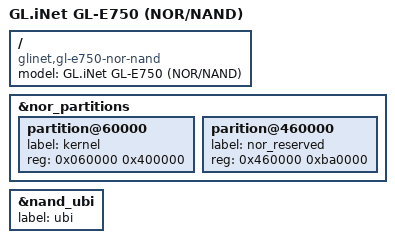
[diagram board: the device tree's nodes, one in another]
// SPDX-License-Identifier: GPL-2.0-or-later OR MIT

/dts-v1/;

#include "qca9531_glinet_gl-e750.dtsi"

/ {
	compatible = "glinet,gl-e750-nor-nand", "qca,qca9531";
	model = "GL.iNet GL-E750 (NOR/NAND)";
};

&nor_partitions {
	partition@60000 {
		label = "kernel";
		reg = <0x060000 0x400000>;
	};
	parition@460000 {
		label = "nor_reserved";
		reg = <0x460000 0xba0000>;
	};
};

&nand_ubi {
	label = "ubi";
};
